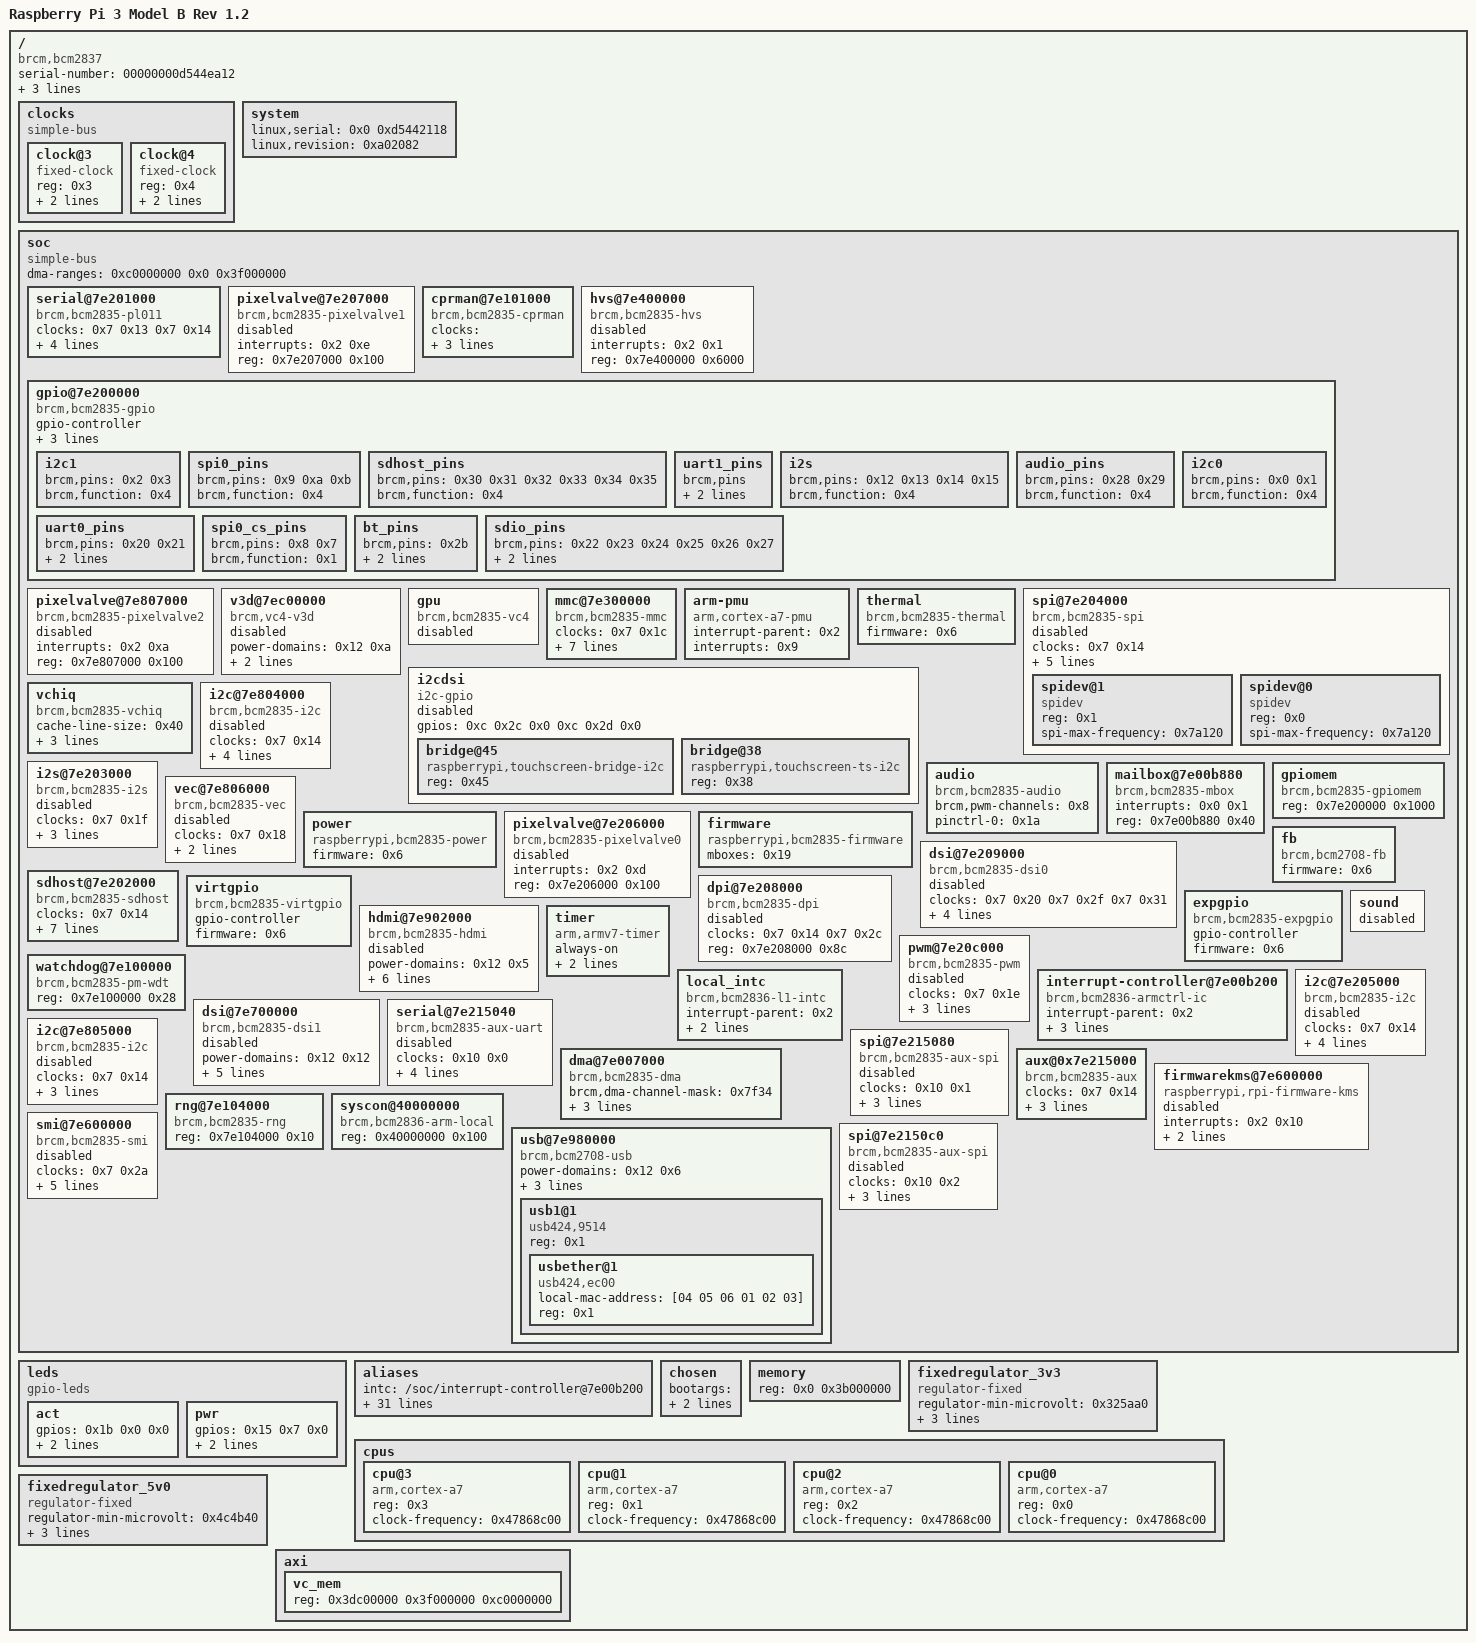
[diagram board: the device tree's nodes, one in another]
/dts-v1/;

/ {
	compatible = "brcm,bcm2837", "brcm,bcm2836";
	serial-number = "00000000d544ea12";
	model = "Raspberry Pi 3 Model B Rev 1.2";
	memreserve = <0x3b000000 0x4000000>;
	interrupt-parent = <0x1>;
	#address-cells = <0x1>;
	#size-cells = <0x1>;

	clocks {
		compatible = "simple-bus";
		#address-cells = <0x1>;
		#size-cells = <0x0>;

		clock@3 {
			compatible = "fixed-clock";
			#clock-cells = <0x0>;
			phandle = <0x3>;
			reg = <0x3>;
			clock-output-names = "osc";
			clock-frequency = <0x124f800>;
		};

		clock@4 {
			compatible = "fixed-clock";
			#clock-cells = <0x0>;
			phandle = <0x16>;
			reg = <0x4>;
			clock-output-names = "otg";
			clock-frequency = <0x1c9c3800>;
		};
	};

	__overrides__ {
		pwr_led_gpio = "", "", "", "(gpios:4";
		i2c1 = "", "", "", "&status";
		i2c_vc = "", "", "", "%status";
		sd_overclock = "", "", "", ",brcm,overclock-50:0";
		i2c0_baudrate = "", "", "", "%clock-frequency:0";
		sd_pio_limit = "", "", "", ",brcm,pio-limit:0";
		act_led_trigger = "", "", "", "'linux,default-trigger";
		audio = "", "", "", ")status";
		sd_debug = "", "", "", ",brcm,debug";
		cache_line_size = [00 00 00 1c 63 61 63 68 65 2d 6c 69 6e 65 2d 73 69 7a 65 3a 30 00];
		i2c1_baudrate = "", "", "", "&clock-frequency:0";
		spi = "", "", "", "$status";
		i2c_arm = "", "", "", "&status";
		pwr_led_activelow = "", "", "", "(gpios:8";
		uart0 = "", "", "", "!status";
		i2c2_iknowwhatimdoing = [00 00 00 14 73 74 61 74 75 73 00];
		i2s = "", "", "", "#status";
		i2c0 = "", "", "", "%status";
		arm_freq = <0x1d 0x636c6f63 0x6b2d6672 0x65717565 0x6e63793a 0x30000000 0x1e636c 0x6f636b2d 0x66726571 0x75656e63 0x793a3000 0x1f 0x636c6f63 0x6b2d6672 0x65717565 0x6e63793a 0x30000000 0x20636c 0x6f636b2d 0x66726571 0x75656e63 0x793a3000>;
		watchdog = "", "", "", "*status";
		i2c_baudrate = "", "", "", "&clock-frequency:0";
		i2c_vc_baudrate = "", "", "", "%clock-frequency:0";
		act_led_activelow = "", "", "", "'gpios:8";
		i2c2_baudrate = [00 00 00 14 63 6c 6f 63 6b 2d 66 72 65 71 75 65 6e 63 79 3a 30 00];
		sd_force_pio = "", "", "", ",brcm,force-pio?";
		pwr_led_trigger = "", "", "", "(linux,default-trigger";
		uart1 = "", "", "", "\"status";
		i2c_arm_baudrate = "", "", "", "&clock-frequency:0";
		random = "", "", "", "+status";
		act_led_gpio = "", "", "", "'gpios:4";
		i2c = "", "", "", "&status";
	};

	system {
		linux,serial = <0x0 0xd5442118>;
		linux,revision = <0xa02082>;
	};

	__symbols__ {
		pwm = "/soc/pwm@7e20c000";
		clk_usb = "/clocks/clock@4";
		pixelvalve0 = "/soc/pixelvalve@7e206000";
		intc = "/soc/interrupt-controller@7e00b200";
		spi2 = "/soc/spi@7e2150c0";
		dsi1 = "/soc/dsi@7e700000";
		clocks = "/soc/cprman@7e101000";
		i2c1 = "/soc/i2c@7e804000";
		i2c_vc = "/soc/i2c@7e205000";
		firmwarekms = "/soc/firmwarekms@7e600000";
		smi = "/soc/smi@7e600000";
		gpu = "/soc/gpu";
		spi0 = "/soc/spi@7e204000";
		thermal = "/soc/thermal";
		vdd_5v0_reg = "/fixedregulator_5v0";
		vchiq = "/soc/vchiq";
		sdhost = "/soc/sdhost@7e202000";
		aux = "/soc/aux@0x7e215000";
		gpio = "/soc/gpio@7e200000";
		dpi = "/soc/dpi@7e208000";
		v3d = "/soc/v3d@7ec00000";
		audio = "/soc/audio";
		vdd_3v3_reg = "/fixedregulator_3v3";
		dma = "/soc/dma@7e007000";
		spidev1 = "/soc/spi@7e204000/spidev@1";
		v7_cpu3 = "/cpus/cpu@3";
		vc4 = "/soc/gpu";
		power = "/soc/power";
		soc = "/soc";
		v7_cpu1 = "/cpus/cpu@1";
		leds = "/leds";
		i2s_pins = "/soc/gpio@7e200000/i2s";
		firmware = "/soc/firmware";
		cprman = "/soc/cprman@7e101000";
		mmc = "/soc/mmc@7e300000";
		pixelvalve1 = "/soc/pixelvalve@7e207000";
		spi = "/soc/spi@7e204000";
		spi0_pins = "/soc/gpio@7e200000/spi0_pins";
		pitouchscreen_touch = "/soc/i2cdsi/bridge@38";
		i2c_arm = "/soc/i2c@7e804000";
		clk_osc = "/clocks/clock@3";
		ethernet = "/soc/usb@7e980000/usb1@1/usbether@1";
		uart0 = "/soc/serial@7e201000";
		i2c1_pins = "/soc/gpio@7e200000/i2c1";
		fb = "/soc/fb";
		sdhost_pins = "/soc/gpio@7e200000/sdhost_pins";
		i2c2 = "/soc/i2c@7e805000";
		uart1_pins = "/soc/gpio@7e200000/uart1_pins";
		i2s = "/soc/i2s@7e203000";
		spi1 = "/soc/spi@7e215080";
		virtgpio = "/soc/virtgpio";
		usb = "/soc/usb@7e980000";
		dsi0 = "/soc/dsi@7e209000";
		expgpio = "/soc/expgpio";
		audio_pins = "/soc/gpio@7e200000/audio_pins";
		i2c0 = "/soc/i2c@7e205000";
		i2c0_pins = "/soc/gpio@7e200000/i2c0";
		pwr_led = "/leds/pwr";
		watchdog = "/soc/watchdog@7e100000";
		uart0_pins = "/soc/gpio@7e200000/uart0_pins";
		vec = "/soc/vec@7e806000";
		local_intc = "/soc/local_intc";
		i2c_dsi = "/soc/i2cdsi";
		pitouchscreen_bridge = "/soc/i2cdsi/bridge@45";
		spi0_cs_pins = "/soc/gpio@7e200000/spi0_cs_pins";
		sound = "/soc/sound";
		hvs = "/soc/hvs@7e400000";
		act_led = "/leds/act";
		spidev0 = "/soc/spi@7e204000/spidev@0";
		v7_cpu2 = "/cpus/cpu@2";
		bt_pins = "/soc/gpio@7e200000/bt_pins";
		sdio_pins = "/soc/gpio@7e200000/sdio_pins";
		cpus = "/cpus";
		hdmi = "/soc/hdmi@7e902000";
		pixelvalve2 = "/soc/pixelvalve@7e807000";
		v7_cpu0 = "/cpus/cpu@0";
		mailbox = "/soc/mailbox@7e00b880";
		uart1 = "/soc/serial@7e215040";
		random = "/soc/rng@7e104000";
		i2c = "/soc/i2c@7e804000";
	};

	soc {
		compatible = "simple-bus";
		ranges = <0x7e000000 0x3f000000 0x1000000 0x40000000 0x40000000 0x40000>;
		#address-cells = <0x1>;
		#size-cells = <0x1>;
		phandle = <0x2d>;
		dma-ranges = <0xc0000000 0x0 0x3f000000>;

		serial@7e201000 {
			compatible = "brcm,bcm2835-pl011", "arm,pl011", "arm,primecell";
			clocks = <0x7 0x13 0x7 0x14>;
			clock-names = "uartclk", "apb_pclk";
			status = "okay";
			interrupts = <0x2 0x19>;
			phandle = <0x21>;
			arm,primecell-periphid = <0x241011>;
			reg = <0x7e201000 0x1000>;
			pinctrl-0 = <0x8 0x9>;
			pinctrl-names = "default";
		};

		pixelvalve@7e207000 {
			compatible = "brcm,bcm2835-pixelvalve1";
			status = "disabled";
			interrupts = <0x2 0xe>;
			phandle = <0x31>;
			reg = <0x7e207000 0x100>;
		};

		cprman@7e101000 {
			compatible = "brcm,bcm2835-cprman";
			clocks = <0x3 0x4 0x0 0x4 0x1 0x4 0x2 0x5 0x0 0x5 0x1 0x5 0x2>;
			firmware = <0x6>;
			#clock-cells = <0x1>;
			phandle = <0x7>;
			reg = <0x7e101000 0x2000>;
		};

		hvs@7e400000 {
			compatible = "brcm,bcm2835-hvs";
			status = "disabled";
			interrupts = <0x2 0x1>;
			phandle = <0x35>;
			reg = <0x7e400000 0x6000>;
		};

		gpio@7e200000 {
			compatible = "brcm,bcm2835-gpio";
			gpio-controller;
			#interrupt-cells = <0x2>;
			interrupts = <0x2 0x11 0x2 0x12>;
			phandle = <0xc>;
			reg = <0x7e200000 0xb4>;
			#gpio-cells = <0x2>;
			interrupt-controller;

			i2c1 {
				brcm,pins = <0x2 0x3>;
				phandle = <0x13>;
				brcm,function = <0x4>;
			};

			spi0_pins {
				brcm,pins = <0x9 0xa 0xb>;
				phandle = <0xd>;
				brcm,function = <0x4>;
			};

			sdhost_pins {
				brcm,pins = <0x30 0x31 0x32 0x33 0x34 0x35>;
				phandle = <0x17>;
				brcm,function = <0x4>;
			};

			uart1_pins {
				brcm,pins;
				phandle = <0x11>;
				brcm,pull;
				brcm,function;
			};

			i2s {
				brcm,pins = <0x12 0x13 0x14 0x15>;
				phandle = <0xb>;
				brcm,function = <0x4>;
			};

			audio_pins {
				brcm,pins = <0x28 0x29>;
				phandle = <0x1a>;
				brcm,function = <0x4>;
			};

			i2c0 {
				brcm,pins = <0x0 0x1>;
				phandle = <0xf>;
				brcm,function = <0x4>;
			};

			uart0_pins {
				brcm,pins = <0x20 0x21>;
				phandle = <0x8>;
				brcm,pull = <0x0 0x2>;
				brcm,function = <0x7>;
			};

			spi0_cs_pins {
				brcm,pins = <0x8 0x7>;
				phandle = <0xe>;
				brcm,function = <0x1>;
			};

			bt_pins {
				brcm,pins = <0x2b>;
				phandle = <0x9>;
				brcm,pull = <0x0>;
				brcm,function = <0x4>;
			};

			sdio_pins {
				brcm,pins = <0x22 0x23 0x24 0x25 0x26 0x27>;
				phandle = <0x18>;
				brcm,pull = <0x0 0x2 0x2 0x2 0x2 0x2>;
				brcm,function = <0x7>;
			};
		};

		pixelvalve@7e807000 {
			compatible = "brcm,bcm2835-pixelvalve2";
			status = "disabled";
			interrupts = <0x2 0xa>;
			phandle = <0x37>;
			reg = <0x7e807000 0x100>;
		};

		v3d@7ec00000 {
			power-domains = <0x12 0xa>;
			compatible = "brcm,vc4-v3d";
			status = "disabled";
			interrupts = <0x1 0xa>;
			phandle = <0x3b>;
			reg = <0x7ec00000 0x1000>;
		};

		gpu {
			compatible = "brcm,bcm2835-vc4";
			status = "disabled";
			phandle = <0x3c>;
		};

		mmc@7e300000 {
			compatible = "brcm,bcm2835-mmc";
			clocks = <0x7 0x1c>;
			status = "okay";
			interrupts = <0x2 0x1e>;
			brcm,overclock-50 = <0x0>;
			bus-width = <0x4>;
			dma-names = "rx-tx";
			phandle = <0x3e>;
			reg = <0x7e300000 0x100>;
			pinctrl-0 = <0x18>;
			dmas = <0xa 0xb>;
			non-removable;
			pinctrl-names = "default";
		};

		arm-pmu {
			compatible = "arm,cortex-a7-pmu";
			interrupt-parent = <0x2>;
			interrupts = <0x9>;
		};

		thermal {
			compatible = "brcm,bcm2835-thermal";
			firmware = <0x6>;
			phandle = <0x45>;
		};

		spi@7e204000 {
			compatible = "brcm,bcm2835-spi";
			clocks = <0x7 0x14>;
			status = "disabled";
			#address-cells = <0x1>;
			interrupts = <0x2 0x16>;
			cs-gpios = <0xc 0x8 0x1 0xc 0x7 0x1>;
			#size-cells = <0x0>;
			dma-names = "tx", "rx";
			phandle = <0x24>;
			reg = <0x7e204000 0x1000>;
			pinctrl-0 = <0xd 0xe>;
			dmas = <0xa 0x6 0xa 0x7>;
			pinctrl-names = "default";

			spidev@1 {
				compatible = "spidev";
				#address-cells = <0x1>;
				#size-cells = <0x0>;
				phandle = <0x2f>;
				reg = <0x1>;
				spi-max-frequency = <0x7a120>;
			};

			spidev@0 {
				compatible = "spidev";
				#address-cells = <0x1>;
				#size-cells = <0x0>;
				phandle = <0x2e>;
				reg = <0x0>;
				spi-max-frequency = <0x7a120>;
			};
		};

		i2cdsi {
			gpios = <0xc 0x2c 0x0 0xc 0x2d 0x0>;
			compatible = "i2c-gpio";
			status = "disabled";
			#address-cells = <0x1>;
			#size-cells = <0x0>;
			phandle = <0x41>;

			bridge@45 {
				compatible = "raspberrypi,touchscreen-bridge-i2c";
				phandle = <0x42>;
				reg = <0x45>;
			};

			bridge@38 {
				compatible = "raspberrypi,touchscreen-ts-i2c";
				phandle = <0x43>;
				reg = <0x38>;
			};
		};

		vchiq {
			compatible = "brcm,bcm2835-vchiq";
			cache-line-size = <0x40>;
			firmware = <0x6>;
			interrupts = <0x0 0x2>;
			phandle = <0x1c>;
			reg = <0x7e00b840 0xf>;
		};

		i2c@7e804000 {
			compatible = "brcm,bcm2835-i2c";
			clocks = <0x7 0x14>;
			status = "disabled";
			#address-cells = <0x1>;
			interrupts = <0x2 0x15>;
			#size-cells = <0x0>;
			phandle = <0x26>;
			reg = <0x7e804000 0x1000>;
			clock-frequency = <0x186a0>;
			pinctrl-0 = <0x13>;
			pinctrl-names = "default";
		};

		audio {
			brcm,pwm-channels = <0x8>;
			compatible = "brcm,bcm2835-audio";
			status = "okay";
			phandle = <0x29>;
			pinctrl-0 = <0x1a>;
			pinctrl-names = "default";
		};

		i2s@7e203000 {
			compatible = "brcm,bcm2835-i2s";
			clocks = <0x7 0x1f>;
			#sound-dai-cells = <0x0>;
			status = "disabled";
			dma-names = "tx", "rx";
			phandle = <0x23>;
			reg = <0x7e203000 0x24>;
			pinctrl-0 = <0xb>;
			dmas = <0xa 0x2 0xa 0x3>;
			pinctrl-names = "default";
		};

		mailbox@7e00b880 {
			compatible = "brcm,bcm2835-mbox";
			#mbox-cells = <0x0>;
			interrupts = <0x0 0x1>;
			phandle = <0x19>;
			reg = <0x7e00b880 0x40>;
		};

		gpiomem {
			compatible = "brcm,bcm2835-gpiomem";
			reg = <0x7e200000 0x1000>;
		};

		vec@7e806000 {
			compatible = "brcm,bcm2835-vec";
			clocks = <0x7 0x18>;
			status = "disabled";
			interrupts = <0x2 0x1b>;
			phandle = <0x36>;
			reg = <0x7e806000 0x1000>;
		};

		power {
			compatible = "raspberrypi,bcm2835-power";
			firmware = <0x6>;
			phandle = <0x12>;
			#power-domain-cells = <0x1>;
		};

		pixelvalve@7e206000 {
			compatible = "brcm,bcm2835-pixelvalve0";
			status = "disabled";
			interrupts = <0x2 0xd>;
			phandle = <0x30>;
			reg = <0x7e206000 0x100>;
		};

		firmware {
			compatible = "raspberrypi,bcm2835-firmware";
			mboxes = <0x19>;
			phandle = <0x6>;
		};

		dsi@7e209000 {
			compatible = "brcm,bcm2835-dsi0";
			clocks = <0x7 0x20 0x7 0x2f 0x7 0x31>;
			clock-names = "phy", "escape", "pixel";
			status = "disabled";
			#address-cells = <0x1>;
			interrupts = <0x2 0x4>;
			#size-cells = <0x0>;
			#clock-cells = <0x1>;
			phandle = <0x4>;
			reg = <0x7e209000 0x78>;
			clock-output-names = "dsi0_byte", "dsi0_ddr2", "dsi0_ddr";
		};

		fb {
			compatible = "brcm,bcm2708-fb";
			firmware = <0x6>;
			status = "okay";
			phandle = <0x44>;
		};

		sdhost@7e202000 {
			compatible = "brcm,bcm2835-sdhost";
			clocks = <0x7 0x14>;
			brcm,pio-limit = <0x1>;
			status = "okay";
			interrupts = <0x2 0x18>;
			brcm,overclock-50 = <0x0>;
			bus-width = <0x4>;
			dma-names = "rx-tx";
			phandle = <0x2c>;
			reg = <0x7e202000 0x100>;
			pinctrl-0 = <0x17>;
			dmas = <0xa 0xd>;
			pinctrl-names = "default";
		};

		virtgpio {
			compatible = "brcm,bcm2835-virtgpio";
			gpio-controller;
			firmware = <0x6>;
			status = "okay";
			phandle = <0x1b>;
			#gpio-cells = <0x2>;
		};

		dpi@7e208000 {
			compatible = "brcm,bcm2835-dpi";
			clocks = <0x7 0x14 0x7 0x2c>;
			clock-names = "core", "pixel";
			status = "disabled";
			#address-cells = <0x1>;
			#size-cells = <0x0>;
			phandle = <0x3d>;
			reg = <0x7e208000 0x8c>;
		};

		expgpio {
			compatible = "brcm,bcm2835-expgpio";
			gpio-controller;
			firmware = <0x6>;
			status = "okay";
			phandle = <0x15>;
			#gpio-cells = <0x2>;
		};

		hdmi@7e902000 {
			power-domains = <0x12 0x5>;
			compatible = "brcm,bcm2835-hdmi";
			clocks = <0x7 0x10 0x7 0x19>;
			clock-names = "pixel", "hdmi";
			ddc = <0x14>;
			status = "disabled";
			interrupts = <0x2 0x8 0x2 0x9>;
			dma-names = "audio-rx";
			phandle = <0x38>;
			hpd-gpios = <0x15 0x4 0x1>;
			reg = <0x7e902000 0x600 0x7e808000 0x100>;
			dmas = <0xa 0x11>;
		};

		timer {
			compatible = "arm,armv7-timer";
			always-on;
			interrupt-parent = <0x2>;
			interrupts = <0x0 0x1 0x3 0x2>;
		};

		pwm@7e20c000 {
			compatible = "brcm,bcm2835-pwm";
			clocks = <0x7 0x1e>;
			status = "disabled";
			assigned-clock-rates = <0x989680>;
			assigned-clocks = <0x7 0x1e>;
			phandle = <0x34>;
			reg = <0x7e20c000 0x28>;
			#pwm-cells = <0x2>;
		};

		watchdog@7e100000 {
			compatible = "brcm,bcm2835-pm-wdt";
			phandle = <0x2a>;
			reg = <0x7e100000 0x28>;
		};

		interrupt-controller@7e00b200 {
			compatible = "brcm,bcm2836-armctrl-ic";
			#interrupt-cells = <0x2>;
			interrupt-parent = <0x2>;
			interrupts = <0x8>;
			phandle = <0x1>;
			reg = <0x7e00b200 0x200>;
			interrupt-controller;
		};

		local_intc {
			compatible = "brcm,bcm2836-l1-intc";
			#interrupt-cells = <0x1>;
			interrupt-parent = <0x2>;
			phandle = <0x2>;
			reg = <0x40000000 0x100>;
			interrupt-controller;
		};

		dsi@7e700000 {
			power-domains = <0x12 0x12>;
			compatible = "brcm,bcm2835-dsi1";
			clocks = <0x7 0x23 0x7 0x30 0x7 0x32>;
			clock-names = "phy", "escape", "pixel";
			status = "disabled";
			#address-cells = <0x1>;
			interrupts = <0x2 0xc>;
			#size-cells = <0x0>;
			#clock-cells = <0x1>;
			phandle = <0x5>;
			reg = <0x7e700000 0x8c>;
			clock-output-names = "dsi1_byte", "dsi1_ddr2", "dsi1_ddr";
		};

		sound {
			status = "disabled";
			phandle = <0x46>;
		};

		i2c@7e205000 {
			compatible = "brcm,bcm2835-i2c";
			clocks = <0x7 0x14>;
			status = "disabled";
			#address-cells = <0x1>;
			interrupts = <0x2 0x15>;
			#size-cells = <0x0>;
			phandle = <0x25>;
			reg = <0x7e205000 0x1000>;
			clock-frequency = <0x186a0>;
			pinctrl-0 = <0xf>;
			pinctrl-names = "default";
		};

		serial@7e215040 {
			compatible = "brcm,bcm2835-aux-uart";
			clocks = <0x10 0x0>;
			status = "disabled";
			interrupt-parent = <0x10>;
			interrupts = <0x0>;
			phandle = <0x22>;
			reg = <0x7e215040 0x40>;
			pinctrl-0 = <0x11>;
			pinctrl-names = "default";
		};

		dma@7e007000 {
			#dma-cells = <0x1>;
			compatible = "brcm,bcm2835-dma";
			brcm,dma-channel-mask = <0x7f34>;
			interrupts = <0x1 0x10 0x1 0x11 0x1 0x12 0x1 0x13 0x1 0x14 0x1 0x15 0x1 0x16 0x1 0x17 0x1 0x18 0x1 0x19 0x1 0x1a 0x1 0x1b 0x1 0x1b 0x1 0x1b 0x1 0x1b 0x1 0x1c>;
			phandle = <0xa>;
			reg = <0x7e007000 0xf00>;
			interrupt-names = "dma0", "dma1", "dma2", "dma3", "dma4", "dma5", "dma6", "dma7", "dma8", "dma9", "dma10", "dma11", "dma12", "dma13", "dma14", "dma-shared-all";
		};

		i2c@7e805000 {
			compatible = "brcm,bcm2835-i2c";
			clocks = <0x7 0x14>;
			status = "disabled";
			#address-cells = <0x1>;
			interrupts = <0x2 0x15>;
			#size-cells = <0x0>;
			phandle = <0x14>;
			reg = <0x7e805000 0x1000>;
			clock-frequency = <0x186a0>;
		};

		spi@7e215080 {
			compatible = "brcm,bcm2835-aux-spi";
			clocks = <0x10 0x1>;
			status = "disabled";
			interrupt-parent = <0x10>;
			#address-cells = <0x1>;
			interrupts = <0x1>;
			#size-cells = <0x0>;
			phandle = <0x32>;
			reg = <0x7e215080 0x40>;
		};

		aux@0x7e215000 {
			compatible = "brcm,bcm2835-aux";
			clocks = <0x7 0x14>;
			#interrupt-cells = <0x1>;
			interrupts = <0x1 0x1d>;
			#clock-cells = <0x1>;
			phandle = <0x10>;
			reg = <0x7e215000 0x8>;
			interrupt-controller;
		};

		firmwarekms@7e600000 {
			compatible = "raspberrypi,rpi-firmware-kms";
			status = "disabled";
			interrupts = <0x2 0x10>;
			brcm,firmware = <0x6>;
			phandle = <0x3f>;
			reg = <0x7e600000 0x100>;
		};

		rng@7e104000 {
			compatible = "brcm,bcm2835-rng";
			phandle = <0x2b>;
			reg = <0x7e104000 0x10>;
		};

		syscon@40000000 {
			compatible = "brcm,bcm2836-arm-local", "syscon";
			reg = <0x40000000 0x100>;
		};

		usb@7e980000 {
			power-domains = <0x12 0x6>;
			compatible = "brcm,bcm2708-usb";
			clocks = <0x16>;
			clock-names = "otg";
			#address-cells = <0x1>;
			interrupts = <0x2 0x0 0x1 0x9>;
			#size-cells = <0x0>;
			phandle = <0x39>;
			reg = <0x7e980000 0x10000 0x7e006000 0x1000>;

			usb1@1 {
				compatible = "usb424,9514";
				#address-cells = <0x1>;
				#size-cells = <0x0>;
				reg = <0x1>;

				usbether@1 {
					compatible = "usb424,ec00";
					local-mac-address = [04 05 06 01 02 03];
					phandle = <0x3a>;
					reg = <0x1>;
				};
			};
		};

		smi@7e600000 {
			compatible = "brcm,bcm2835-smi";
			clocks = <0x7 0x2a>;
			status = "disabled";
			interrupts = <0x2 0x10>;
			assigned-clock-rates = <0x7735940>;
			dma-names = "rx-tx";
			assigned-clocks = <0x7 0x2a>;
			phandle = <0x40>;
			reg = <0x7e600000 0x100>;
			dmas = <0xa 0x4>;
		};

		spi@7e2150c0 {
			compatible = "brcm,bcm2835-aux-spi";
			clocks = <0x10 0x2>;
			status = "disabled";
			interrupt-parent = <0x10>;
			#address-cells = <0x1>;
			interrupts = <0x2>;
			#size-cells = <0x0>;
			phandle = <0x33>;
			reg = <0x7e2150c0 0x40>;
		};
	};

	leds {
		compatible = "gpio-leds";
		phandle = <0x49>;

		act {
			gpios = <0x1b 0x0 0x0>;
			label = "led0";
			phandle = <0x27>;
			linux,default-trigger = "mmc0";
		};

		pwr {
			gpios = <0x15 0x7 0x0>;
			label = "led1";
			phandle = <0x28>;
			linux,default-trigger = "input";
		};
	};

	aliases {
		intc = "/soc/interrupt-controller@7e00b200";
		spi2 = "/soc/spi@7e2150c0";
		i2c1 = "/soc/i2c@7e804000";
		i2c_vc = "/soc/i2c@7e205000";
		spi0 = "/soc/spi@7e204000";
		thermal = "/soc/thermal";
		vchiq = "/soc/vchiq";
		sdhost = "/soc/sdhost@7e202000";
		aux = "/soc/aux@0x7e215000";
		gpio = "/soc/gpio@7e200000";
		audio = "/soc/audio";
		dma = "/soc/dma@7e007000";
		soc = "/soc";
		leds = "/leds";
		mmc = "/soc/mmc@7e300000";
		serial1 = "/soc/serial@7e201000";
		i2c_arm = "/soc/i2c@7e804000";
		ethernet = "/soc/usb@7e980000/usb1@1/usbether@1";
		uart0 = "/soc/serial@7e201000";
		fb = "/soc/fb";
		i2c2 = "/soc/i2c@7e805000";
		i2s = "/soc/i2s@7e203000";
		spi1 = "/soc/spi@7e215080";
		usb = "/soc/usb@7e980000";
		i2c0 = "/soc/i2c@7e205000";
		watchdog = "/soc/watchdog@7e100000";
		sound = "/soc/sound";
		mailbox = "/soc/mailbox@7e00b880";
		uart1 = "/soc/serial@7e215040";
		random = "/soc/rng@7e104000";
		i2c = "/soc/i2c@7e804000";
		serial0 = "/soc/serial@7e215040";
	};

	chosen {
		bootargs = "8250.nr_uarts=0 bcm2708_fb.fbwidth=640 bcm2708_fb.fbheight=480 bcm2708_fb.fbswap=1 vc_mem.mem_base=0x3dc00000 vc_mem.mem_size=0x3f000000  dwc_otg.lpm_enable=0 console=ttyS0,115200 console=tty1 root=/dev/mmcblk0p7 rootfstype=ext4 elevator=deadline fsck.repair=yes rootwait";
		kaslr-seed = <0xef42e779 0x662d8187>;
	};

	memory {
		device_type = "memory";
		reg = <0x0 0x3b000000>;
	};

	fixedregulator_3v3 {
		compatible = "regulator-fixed";
		phandle = <0x48>;
		regulator-min-microvolt = <0x325aa0>;
		regulator-max-microvolt = <0x325aa0>;
		regulator-always-on;
		regulator-name = "3v3";
	};

	cpus {
		#address-cells = <0x1>;
		#size-cells = <0x0>;
		phandle = <0x4a>;

		cpu@3 {
			compatible = "arm,cortex-a7";
			device_type = "cpu";
			phandle = <0x20>;
			reg = <0x3>;
			clock-frequency = <0x47868c00>;
		};

		cpu@1 {
			compatible = "arm,cortex-a7";
			device_type = "cpu";
			phandle = <0x1e>;
			reg = <0x1>;
			clock-frequency = <0x47868c00>;
		};

		cpu@2 {
			compatible = "arm,cortex-a7";
			device_type = "cpu";
			phandle = <0x1f>;
			reg = <0x2>;
			clock-frequency = <0x47868c00>;
		};

		cpu@0 {
			compatible = "arm,cortex-a7";
			device_type = "cpu";
			phandle = <0x1d>;
			reg = <0x0>;
			clock-frequency = <0x47868c00>;
		};
	};

	fixedregulator_5v0 {
		compatible = "regulator-fixed";
		phandle = <0x47>;
		regulator-min-microvolt = <0x4c4b40>;
		regulator-max-microvolt = <0x4c4b40>;
		regulator-always-on;
		regulator-name = "5v0";
	};

	axi {

		vc_mem {
			reg = <0x3dc00000 0x3f000000 0xc0000000>;
		};
	};
};
